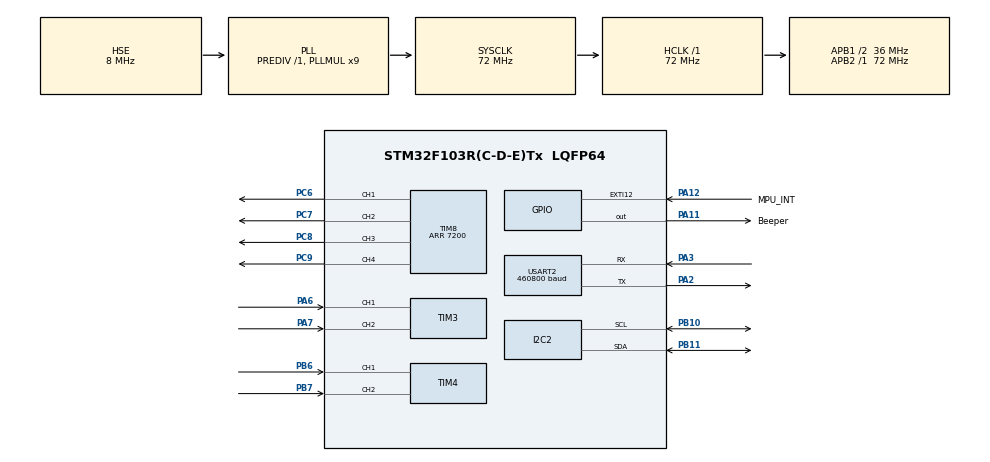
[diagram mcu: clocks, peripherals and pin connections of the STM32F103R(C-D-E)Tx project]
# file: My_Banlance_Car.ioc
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I2C2.I2C_Mode=I2C_Fast
Mcu.Family=STM32F1
Mcu.Name=STM32F103R(C-D-E)Tx
Mcu.Package=LQFP64
NVIC.EXTI15_10_IRQn=true\:0\:0\:false\:false\:true\:true\:true\:true
NVIC.PriorityGroup=NVIC_PRIORITYGROUP_4
NVIC.TIM7_IRQn=true\:0\:0\:false\:false\:true\:true\:true\:true
PA11.GPIO_Label=Beeper
PA11.Signal=GPIO_Output
PA12.GPIO_Label=MPU_INT
PA12.GPIO_ModeDefaultEXTI=GPIO_MODE_IT_RISING
PA12.GPIO_PuPd=GPIO_PULLDOWN
PA12.Signal=GPXTI12
PA13.Mode=Serial_Wire
PA13.Signal=SYS_JTMS-SWDIO
PA14.Mode=Serial_Wire
PA14.Signal=SYS_JTCK-SWCLK
PA2.Mode=Asynchronous
PA2.Signal=USART2_TX
PA3.Mode=Asynchronous
PA3.Signal=USART2_RX
PA6.Signal=S_TIM3_CH1
PA7.Signal=S_TIM3_CH2
PB10.Mode=I2C
PB10.Signal=I2C2_SCL
PB11.Mode=I2C
PB11.Signal=I2C2_SDA
PB6.Signal=S_TIM4_CH1
PB7.Signal=S_TIM4_CH2
PC14-OSC32_IN.Mode=LSE-External-Oscillator
PC14-OSC32_IN.Signal=RCC_OSC32_IN
PC15-OSC32_OUT.Mode=LSE-External-Oscillator
PC15-OSC32_OUT.Signal=RCC_OSC32_OUT
PC6.Signal=S_TIM8_CH1
PC7.Signal=S_TIM8_CH2
PC8.Signal=S_TIM8_CH3
PC9.Signal=S_TIM8_CH4
PD0-OSC_IN.Mode=HSE-External-Oscillator
PD0-OSC_IN.Signal=RCC_OSC_IN
PD1-OSC_OUT.Mode=HSE-External-Oscillator
PD1-OSC_OUT.Signal=RCC_OSC_OUT
ProjectManager.HeapSize=0x200
ProjectManager.StackSize=0x400
ProjectManager.TargetToolchain=MDK-ARM V5.32
RCC.AHBFreq_Value=72000000
RCC.APB1CLKDivider=RCC_HCLK_DIV2
RCC.APB1Freq_Value=36000000
RCC.APB1TimFreq_Value=72000000
RCC.APB2Freq_Value=72000000
RCC.APB2TimFreq_Value=72000000
RCC.HCLKFreq_Value=72000000
RCC.PLLMUL=RCC_PLL_MUL9
RCC.PLLSourceVirtual=RCC_PLLSOURCE_HSE
RCC.SYSCLKFreq_VALUE=72000000
RCC.SYSCLKSource=RCC_SYSCLKSOURCE_PLLCLK
RCC.USBFreq_Value=72000000
SH.S_TIM3_CH1.0=TIM3_CH1,Encoder_Interface
SH.S_TIM3_CH2.0=TIM3_CH2,Encoder_Interface
SH.S_TIM4_CH1.0=TIM4_CH1,Encoder_Interface
SH.S_TIM4_CH2.0=TIM4_CH2,Encoder_Interface
SH.S_TIM8_CH1.0=TIM8_CH1,PWM Generation1 CH1
SH.S_TIM8_CH2.0=TIM8_CH2,PWM Generation2 CH2
SH.S_TIM8_CH3.0=TIM8_CH3,PWM Generation3 CH3
SH.S_TIM8_CH4.0=TIM8_CH4,PWM Generation4 CH4
STMicroelectronics.X-CUBE-ALGOBUILD.1.4.0.LibraryCcDSPOoLibraryJjDSPOoLibrary=true
TIM3.EncoderMode=TIM_ENCODERMODE_TI12
TIM4.EncoderMode=TIM_ENCODERMODE_TI12
TIM6.Prescaler=71
TIM7.Period=4999
TIM7.Prescaler=71
TIM8.AutoReloadPreload=TIM_AUTORELOAD_PRELOAD_ENABLE
TIM8.Channel-PWM\ Generation1\ CH1=TIM_CHANNEL_1
TIM8.Channel-PWM\ Generation2\ CH2=TIM_CHANNEL_2
TIM8.Channel-PWM\ Generation3\ CH3=TIM_CHANNEL_3
TIM8.Channel-PWM\ Generation4\ CH4=TIM_CHANNEL_4
TIM8.Period=7200
USART2.BaudRate=460800
USART2.VirtualMode=VM_ASYNC
VP_STMicroelectronics.X-CUBE-ALGOBUILD_VS_DSPOoLibraryJjLibrary_1.4.0_1.4.0.Mode=DSPOoLibraryJjLibrary
VP_TIM6_VS_ClockSourceINT.Mode=Enable_Timer
VP_TIM7_VS_ClockSourceINT.Mode=Enable_Timer
VP_TIM8_VS_ClockSourceINT.Mode=Internal
board=custom

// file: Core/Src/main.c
/* USER CODE BEGIN Header */
/**
  ******************************************************************************
  * @file           : main.c
  * @brief          : Main program body
  ******************************************************************************
  * @attention
  *
  * Copyright (c) 2025 STMicroelectronics.
  * All rights reserved.
  *
  * This software is licensed under terms that can be found in the LICENSE file
  * in the root directory of this software component.
  * If no LICENSE file comes with this software, it is provided AS-IS.
  *
  ******************************************************************************
  */
/* USER CODE END Header */
#include "main.h"
#include "i2c.h"
#include "tim.h"
#include "usart.h"
#include "gpio.h"

void SystemClock_Config(void);

/* USER CODE BEGIN 0 */

#include "Mask.h"

/* USER CODE END 0 */

int main(void)
{

  /* MCU Configuration--------------------------------------------------------*/

  /* Reset of all peripherals, Initializes the Flash interface and the Systick. */
  HAL_Init();

  /* Configure the system clock */
  SystemClock_Config();

  /* Initialize all configured peripherals */
  MX_GPIO_Init();
  MX_USART2_UART_Init();
  MX_I2C2_Init();
  MX_TIM3_Init();
  MX_TIM4_Init();
  MX_TIM7_Init();
  MX_TIM8_Init();
  MX_TIM6_Init();

  /* Infinite loop */
  /* USER CODE BEGIN WHILE */

	 Mask_start();

  while (1)
  {
    /* USER CODE END WHILE */

  }
}

void SystemClock_Config(void)
{
  RCC_OscInitTypeDef RCC_OscInitStruct = {0};
  RCC_ClkInitTypeDef RCC_ClkInitStruct = {0};

  /** Initializes the RCC Oscillators according to the specified parameters
  * in the RCC_OscInitTypeDef structure.
  */
  RCC_OscInitStruct.OscillatorType = RCC_OSCILLATORTYPE_HSE;
  RCC_OscInitStruct.HSEState = RCC_HSE_ON;
  RCC_OscInitStruct.HSEPredivValue = RCC_HSE_PREDIV_DIV1;
  RCC_OscInitStruct.HSIState = RCC_HSI_ON;
  RCC_OscInitStruct.PLL.PLLState = RCC_PLL_ON;
  RCC_OscInitStruct.PLL.PLLSource = RCC_PLLSOURCE_HSE;
  RCC_OscInitStruct.PLL.PLLMUL = RCC_PLL_MUL9;
  if (HAL_RCC_OscConfig(&RCC_OscInitStruct) != HAL_OK)
  {
    Error_Handler();
  }

  /** Initializes the CPU, AHB and APB buses clocks
  */
  RCC_ClkInitStruct.ClockType = RCC_CLOCKTYPE_HCLK|RCC_CLOCKTYPE_SYSCLK
                              |RCC_CLOCKTYPE_PCLK1|RCC_CLOCKTYPE_PCLK2;
  RCC_ClkInitStruct.SYSCLKSource = RCC_SYSCLKSOURCE_PLLCLK;
  RCC_ClkInitStruct.AHBCLKDivider = RCC_SYSCLK_DIV1;
  RCC_ClkInitStruct.APB1CLKDivider = RCC_HCLK_DIV2;
  RCC_ClkInitStruct.APB2CLKDivider = RCC_HCLK_DIV1;

  if (HAL_RCC_ClockConfig(&RCC_ClkInitStruct, FLASH_LATENCY_2) != HAL_OK)
  {
    Error_Handler();
  }
}

void Error_Handler(void)
{
  __disable_irq();
  while (1)
  {
  }
}
